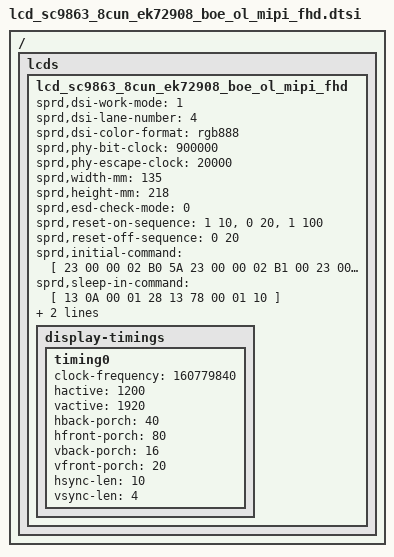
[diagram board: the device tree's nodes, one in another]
/ { lcds {
	lcd_sc9863_8cun_ek72908_boe_ol_mipi_fhd: lcd_sc9863_8cun_ek72908_boe_ol_mipi_fhd {

		sprd,dsi-work-mode = <1>;
		sprd,dsi-lane-number = <4>;
		sprd,dsi-color-format = "rgb888";

		sprd,phy-bit-clock = <900000>;
		sprd,phy-escape-clock = <20000>;

		sprd,width-mm = <135>;
		sprd,height-mm = <218>;

		sprd,esd-check-mode = <0>;

		sprd,reset-on-sequence = <1 10>, <0 20>, <1 100>;
		sprd,reset-off-sequence = <0 20>;


		sprd,initial-command = [
		23 00 00 02 B0 5A 

		23 00 00 02 B1 00 
		23 00 00 02 89 01 
		23 00 00 02 91 17 
		23 00 00 02 B1 03 
		23 00 00 02 2C 28 
		23 00 00 02 00 3C 
		23 00 00 02 01 1E 
		23 00 00 02 02 00 
		23 00 00 02 03 00 
		23 00 00 02 04 00 
		23 00 00 02 05 00 
		23 00 00 02 06 00 
		23 00 00 02 07 00 
		23 00 00 02 08 80 
		23 00 00 02 09 04 
		23 00 00 02 0A 0B 
		23 00 00 02 0B 3C 
		23 00 00 02 0C 00 
		23 00 00 02 0D 00 
		23 00 00 02 0E 24 
		23 00 00 02 0F 1C 
		23 00 00 02 10 C9 
		23 00 00 02 11 60 
		23 00 00 02 12 70 
		23 00 00 02 13 01 
		23 00 00 02 14 E3 
		23 00 00 02 15 FF 
		23 00 00 02 16 3D 
		23 00 00 02 17 0E 
		23 00 00 02 18 01 
		23 00 00 02 19 00 
		23 00 00 02 1A 00 
		23 00 00 02 1B FC 
		23 00 00 02 1C 0B 
		23 00 00 02 1D A0 
		23 00 00 02 1E 03 
		23 00 00 02 1F 04 
		23 00 00 02 20 0C 
		23 00 00 02 21 00 
		23 00 00 02 22 04 
		23 00 00 02 23 81 
		23 00 00 02 24 1F 
		23 00 00 02 25 10 
		23 00 00 02 26 9B 
		23 00 00 02 2D 01 
		23 00 00 02 2E 84 
		23 00 00 02 2F 00 
		23 00 00 02 30 02 
		23 00 00 02 31 08 
		23 00 00 02 32 01 
		23 00 00 02 33 1C 
		23 00 00 02 34 70 
		23 00 00 02 35 FF 
		23 00 00 02 36 FF 
		23 00 00 02 37 FF 
		23 00 00 02 38 FF 
		23 00 00 02 39 FF 
		23 00 00 02 3A 05 
		23 00 00 02 3B 00 
		23 00 00 02 3C 00 
		23 00 00 02 3D 00 
		23 00 00 02 3E 0F 
		23 00 00 02 3F 8C 
		23 00 00 02 40 28 
		23 00 00 02 41 FC 
		23 00 00 02 42 01 
		23 00 00 02 43 40 
		23 00 00 02 44 05 
		23 00 00 02 45 E8 
		23 00 00 02 46 16 
		23 00 00 02 47 00 
		23 00 00 02 48 00 
		23 00 00 02 49 88 
		23 00 00 02 4A 08 
		23 00 00 02 4B 05 
		23 00 00 02 4C 03 
		23 00 00 02 4D D0 
		23 00 00 02 4E 13 
		23 00 00 02 4F FF 
		23 00 00 02 50 0A 
		23 00 00 02 51 53 
		23 00 00 02 52 26 
		23 00 00 02 53 22 
		23 00 00 02 54 09 
		23 00 00 02 55 22 
		23 00 00 02 56 00 
		23 00 00 02 57 1C 
		23 00 00 02 58 03 
		23 00 00 02 59 3F 
		23 00 00 02 5A 28 
		23 00 00 02 5B 01 
		23 00 00 02 5C CC 
		23 00 00 02 5D CE 
		23 00 00 02 5E 31 
		23 00 00 02 5F A6 
		23 00 00 02 60 54 
		23 00 00 02 61 08 
		23 00 00 02 62 DE 
		23 00 00 02 63 43 
		23 00 00 02 64 F8 
		23 00 00 02 65 3F 
		23 00 00 02 66 00 
		23 00 00 02 67 42 
		23 00 00 02 68 18 
		23 00 00 02 69 F3 
		23 00 00 02 6A 5E 
		23 00 00 02 6B 6B 
		23 00 00 02 6C 6B 
		23 00 00 02 6D 85 
		23 00 00 02 6E E0 
		23 00 00 02 6F 7D 
		23 00 00 02 70 8C 
		23 00 00 02 71 FF 
		23 00 00 02 72 03 
		23 00 00 02 73 40 
		23 00 00 02 74 08 
		23 00 00 02 75 42 
		23 00 00 02 76 81 
		23 00 00 02 77 04 
		23 00 00 02 78 0F 
		23 00 00 02 79 E0 
		23 00 00 02 7A 01 
		23 00 00 02 7B FF 
		23 00 00 02 7C FF 
		23 00 00 02 7D FF 
		23 00 00 02 7E FF 
		23 00 00 02 7F FE 


		23 00 00 02 B1 02 

		23 00 00 02 00 FF 
		23 00 00 02 01 01 
		23 00 00 02 02 00 
		23 00 00 02 03 00 
		23 00 00 02 04 00 
		23 00 00 02 05 00 
		23 00 00 02 06 00 
		23 00 00 02 07 00 
		23 00 00 02 08 C0 
		23 00 00 02 09 00 
		23 00 00 02 0A 00 
		23 00 00 02 0B 14 
		23 00 00 02 0C E6 
		23 00 00 02 0D 0D 
		23 00 00 02 0F 08 
		23 00 00 02 10 62 
		23 00 00 02 11 47 
		23 00 00 02 12 EC 
		23 00 00 02 13 A4 
		23 00 00 02 14 6E 
		23 00 00 02 15 DB 
		23 00 00 02 16 C1 
		23 00 00 02 17 EC 
		23 00 00 02 18 DE 
		23 00 00 02 19 60 
		23 00 00 02 1A D6 
		23 00 00 02 1B 0B 
		23 00 00 02 1C FF 
		23 00 00 02 1D FF 
		23 00 00 02 1E FF 
		23 00 00 02 1F FF 
		23 00 00 02 20 FF 
		23 00 00 02 21 FF 
		23 00 00 02 22 FF 
		23 00 00 02 23 FF 
		23 00 00 02 24 FF 
		23 00 00 02 25 FF 
		23 00 00 02 26 FF 
		23 00 00 02 27 1F 
		23 00 00 02 28 C8 
		23 00 00 02 29 FF 
		23 00 00 02 2A FF 
		23 00 00 02 2B FF 
		23 00 00 02 2C FF 
		23 00 00 02 2D 07 
		23 00 00 02 33 06 
		23 00 00 02 35 7F 
		23 00 00 02 36 0E 
		23 00 00 02 38 7F 
		23 00 00 02 3A 80 
		23 00 00 02 3B 59 
		23 00 00 02 3C C2 
		23 00 00 02 3D 32 
		23 00 00 02 3E 00 
		23 00 00 02 3F 58 
		23 00 00 02 40 06 
		23 00 00 02 41 00 
		23 00 00 02 42 CB 
		23 00 00 02 43 2C 
		23 00 00 02 44 61 
		23 00 00 02 45 09 
		23 00 00 02 46 00 
		23 00 00 02 47 00 
		23 00 00 02 48 9B 
		23 00 00 02 49 D2 
		23 00 00 02 4A 01 
		23 00 00 02 4B 00 
		23 00 00 02 4C 10 
		23 00 00 02 4D C0 
		23 00 00 02 4E 0F 
		23 00 00 02 4F 61 
		23 00 00 02 50 78 
		23 00 00 02 51 5A 
		23 00 00 02 52 B4 
		23 00 00 02 53 79 
		23 00 00 02 54 00 
		23 00 00 02 55 07 
		23 00 00 02 56 14 
		23 00 00 02 57 38 
		23 00 00 02 58 48 
		23 00 00 02 59 E0 
		23 00 00 02 5A F1 
		23 00 00 02 5B 78 
		23 00 00 02 5C 3C 
		23 00 00 02 5D 1E 
		23 00 00 02 5E 8F 
		23 00 00 02 5F C7 
		23 00 00 02 60 63 
		23 00 00 02 61 66 
		23 00 00 02 62 36 
		23 00 00 02 63 33 
		23 00 00 02 64 9B 
		23 00 00 02 65 CD 
		23 00 00 02 66 66 
		23 00 00 02 67 33 
		23 00 00 02 68 D8 
		23 00 00 02 69 C0 
		23 00 00 02 6A C0 
		23 00 00 02 6B 78 
		23 00 00 02 6C 78 
		23 00 00 02 6D 78 
		23 00 00 02 6E 78 
		23 00 00 02 6F 78 
		23 00 00 02 70 3C 
		23 00 00 02 71 1E 
		23 00 00 02 72 0F 
		23 00 00 02 73 00 
		23 00 00 02 74 00 
		23 00 00 02 75 00 
		23 00 00 02 76 00 
		23 00 00 02 77 00 
		23 00 00 02 78 00 
		23 00 00 02 79 00 
		23 00 00 02 7A CC 
		23 00 00 02 7B CC 
		23 00 00 02 7C CC 
		23 00 00 02 7D CC 
		23 00 00 02 7E CC 
		23 00 00 02 7F 66 
		23 00 00 02 0B 04 

		23 00 00 02 B1 03 
		23 00 00 02 2C 2C 

		23 00 00 02 B1 00 
		23 00 00 02 89 03 
			13 78 00 01 11
			13 64 00 01 29
			];
		sprd,sleep-in-command = [
			13 0A 00 01 28
			13 78 00 01 10
			];
		sprd,sleep-out-command = [
			13 78 00 01 11
			13 64 00 01 29
			];

		display-timings {
			timing0 {
			clock-frequency = <160779840>;
			hactive = <1200>;
			vactive = <1920>;
			hback-porch = <40>;
			hfront-porch = <80>;
			vback-porch = <16>;
			vfront-porch = <20>;
			hsync-len = <10>;
			vsync-len = <4>;
			};
		};
	};
};};

